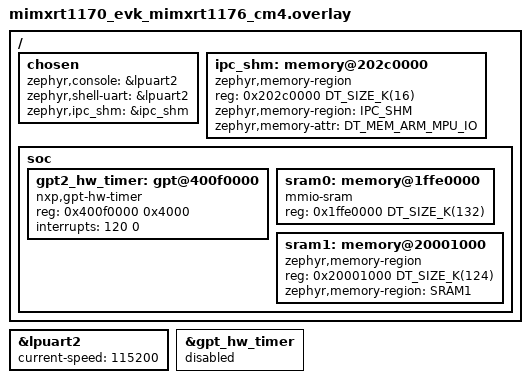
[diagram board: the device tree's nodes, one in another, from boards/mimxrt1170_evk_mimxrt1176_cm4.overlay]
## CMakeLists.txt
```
#
# Copyright 2026 NXP
#
# SPDX-License-Identifier: Apache-2.0
#

cmake_minimum_required(VERSION 3.20.0)
find_package(Zephyr REQUIRED HINTS $ENV{ZEPHYR_BASE})
find_program(ERPCGEN erpcgen REQUIRED)

project(remote)

set(ERPC_DIR ${CMAKE_CURRENT_LIST_DIR}/src/erpc)
add_custom_command(
    OUTPUT
        ${ERPC_DIR}/c_mp_zvid_transform_server.cpp
        ${ERPC_DIR}/mp_zvid_transform_server.cpp
        ${ERPC_DIR}/mp_zvid_transform_interface.cpp
    COMMAND
        ${ERPCGEN} -v -g c -o ${ERPC_DIR} ${ERPC_DIR}/mp_zvid_transform_server.erpc
    COMMAND
        ${CMAKE_COMMAND} -E rm -f ${ERPC_DIR}/*client.cpp ${ERPC_DIR}/*client.h ${ERPC_DIR}/*client.hpp
    DEPENDS
        ${ERPC_DIR}/mp_zvid_transform_server.erpc
)

target_sources(app PRIVATE
    src/main.c
    src/jpeg.c
    ${ERPC_DIR}/erpc_error_handler.c
    ${ERPC_DIR}/c_mp_zvid_transform_server.cpp
    ${ERPC_DIR}/mp_zvid_transform_server.cpp
    ${ERPC_DIR}/mp_zvid_transform_interface.cpp
)

# TODO: eRPC and rpmsg-lite should fix this dependency inversion by using Kconfig instead of
# including application-specific erpc_config.h and rpmsg_config.h back to the libraries
zephyr_include_directories(${CMAKE_CURRENT_SOURCE_DIR}/src/erpc)
zephyr_include_directories(${CMAKE_CURRENT_SOURCE_DIR}/src/erpc/rpmsg_lite)
```

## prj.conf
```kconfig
CONFIG_MAIN_STACK_SIZE=6000
CONFIG_HEAP_MEM_POOL_SIZE=8192

# RPC Configs

# C++ Language Support
CONFIG_CPP=y
CONFIG_NEWLIB_LIBC=y
CONFIG_GLIBCXX_LIBCPP=y

# eRPC
CONFIG_ERPC=y
CONFIG_ERPC_TRANSPORT_RPMSG_LITE=y

# RPMSG Lite
CONFIG_IPM=y
CONFIG_EVENTS=y
CONFIG_PRINTK=y
CONFIG_RPMSGLITE=y
CONFIG_RPMSGLITE_QUEUE=y
CONFIG_RPMSGLITE_NS=y
CONFIG_TIMESLICE_SIZE=1
```

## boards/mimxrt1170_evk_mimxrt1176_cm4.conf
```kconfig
# Multi-core support
CONFIG_BUILD_OUTPUT_INFO_HEADER=y
CONFIG_BUILD_OUTPUT_HEX=y
CONFIG_SECOND_CORE_MCUX=y
```

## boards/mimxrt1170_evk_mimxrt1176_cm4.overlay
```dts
/*
 * Copyright 2026 NXP
 *
 * SPDX-License-Identifier: Apache-2.0
 */

#include <zephyr/dt-bindings/memory-attr/memory-attr-arm.h>

/ {
	chosen {
		zephyr,console = &lpuart2;
		zephyr,shell-uart = &lpuart2;
		zephyr,ipc_shm = &ipc_shm;
	};

	/* OpenAMP fails with full 512K OCRAM2 memory region as shared memory */
	ipc_shm: memory@202c0000{
		compatible = "zephyr,memory-region", "mmio-sram";
		reg = <0x202c0000 DT_SIZE_K(16)>;
		zephyr,memory-region="IPC_SHM";
		zephyr,memory-attr = <DT_MEM_ARM_MPU_IO>;
	};

	soc {
		/delete-node/ gpt@400f0000;

		/* Replace GPT2 with another GPT kernel timer */
		gpt2_hw_timer: gpt@400f0000 {
			compatible = "nxp,gpt-hw-timer";
			reg = <0x400f0000 0x4000>;
			interrupts = <120 0>;
			status = "okay";
		};

		/* Expand M4 ITCM RAM_L to 4K more than default */
		sram0: memory@1ffe0000 {
			compatible = "mmio-sram";
			reg = <0x1ffe0000 DT_SIZE_K(132)>;
		};

		/* Shrink M4 DTCM RAM_U to 4K less than default */
		/delete-node/ memory@20000000;
		sram1: memory@20001000 {
			compatible = "zephyr,memory-region", "mmio-sram";
			reg = <0x20001000 DT_SIZE_K(124)>;
			zephyr,memory-region = "SRAM1";
		};
	};
};

/* Enable secondary LPUART */
&lpuart2 {
	status = "okay";
	current-speed = <115200>;
};

/* Disable primary GPT timer */
&gpt_hw_timer {
	status = "disabled";
};
```

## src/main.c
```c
/*
 * Copyright 2026 NXP
 *
 * SPDX-License-Identifier: BSD-3-Clause
 */

#include <errno.h>
#include <stdint.h>

#include <zephyr/devicetree.h>

#include "JPEGDEC.h"

#include "erpc_server_setup.h"
#include "erpc/c_mp_zvid_transform_server.h"
#include "erpc/erpc_error_handler.h"
#include "erpc/mp_zvid_transform_common.h"

#include "rpmsg_lite.h"

/* TODO: rpmsg-lite should define the link ID in devicetree instead of in rpmsg_platform.h */
#define ERPC_TRANSPORT_RPMSG_LITE_LINK_ID (RL_PLATFORM_IMXRT1170_M7_M4_LINK_ID)

#define SHM_MEM_ADDR DT_REG_ADDR(DT_CHOSEN(zephyr_ipc_shm))
#define SHM_MEM_SIZE DT_REG_SIZE(DT_CHOSEN(zephyr_ipc_shm))

/* Video stuffs picked from Zephyr's video.h */
#define VIDEO_FOURCC(a, b, c, d)                                                                   \
	((uint32_t)(a) | ((uint32_t)(b) << 8) | ((uint32_t)(c) << 16) | ((uint32_t)(d) << 24))

#define VIDEO_PIX_FMT_JPEG   VIDEO_FOURCC('J', 'P', 'E', 'G')
#define VIDEO_PIX_FMT_RGB565 VIDEO_FOURCC('R', 'G', 'B', 'P')

enum video_buf_type {
	/** input buffer type */
	VIDEO_BUF_TYPE_INPUT = 1,
	/** output buffer type */
	VIDEO_BUF_TYPE_OUTPUT = 2,
};

/* End of copied video stuffs */

#define JPEGDEC_WIDTH_MIN  64U
#define JPEGDEC_WIDTH_MAX  8192U
#define JPEGDEC_WIDTH_STEP 16U

#define JPEGDEC_FORMAT_CAP(pixfmt)                                                                 \
	{                                                                                          \
		.pixelformat = pixfmt,                                                             \
		.width_min = JPEGDEC_WIDTH_MIN,                                                    \
		.width_max = JPEGDEC_WIDTH_MAX,                                                    \
		.width_step = JPEGDEC_WIDTH_STEP,                                                  \
		.height_min = JPEGDEC_WIDTH_MIN,                                                   \
		.height_max = JPEGDEC_WIDTH_MAX,                                                   \
		.height_step = JPEGDEC_WIDTH_STEP,                                                 \
	}

static const video_format_cap jpegdec_in_caps[] = {
	JPEGDEC_FORMAT_CAP(VIDEO_PIX_FMT_JPEG),
};

static const video_format_cap jpegdec_out_caps[] = {
	JPEGDEC_FORMAT_CAP(VIDEO_PIX_FMT_RGB565),
};

static video_format out_fmt;
static JPEGIMAGE jpg;

int32_t get_buf_caps_rpc(mp_pad_direction direction, uint8_t *min_buffers, uint16_t *buf_align)
{
	*min_buffers = 1;
	*buf_align = 0;

	return 0;
}

int32_t get_format_caps_rpc(mp_pad_direction direction, uint8_t ind, video_format_cap *vfc)
{
	if (vfc == NULL || (direction != MP_PAD_SINK && direction != MP_PAD_SRC)) {
		return -EINVAL;
	}

	const video_format_cap *jcaps =
		(direction == MP_PAD_SINK) ? jpegdec_in_caps : jpegdec_out_caps;
	uint8_t size = (direction == MP_PAD_SINK) ? ARRAY_SIZE(jpegdec_in_caps)
						  : ARRAY_SIZE(jpegdec_out_caps);

	if (ind >= size) {
		return -ERANGE;
	}

	*vfc = jcaps[ind];

	return 0;
}

int32_t set_format_rpc(video_format *fmt)
{
	if (fmt->type != VIDEO_BUF_TYPE_INPUT && fmt->type != VIDEO_BUF_TYPE_OUTPUT) {
		return -EINVAL;
	}

	const video_format_cap *vfc =
		(fmt->type == VIDEO_BUF_TYPE_INPUT) ? jpegdec_in_caps : jpegdec_out_caps;
	uint8_t sz = (fmt->type == VIDEO_BUF_TYPE_INPUT) ? ARRAY_SIZE(jpegdec_in_caps)
							 : ARRAY_SIZE(jpegdec_out_caps);
	uint8_t i;

	for (i = 0; i < sz; i++) {
		if (fmt->pixelformat == vfc[i].pixelformat && fmt->width > vfc[i].width_min &&
		    fmt->width < vfc[i].width_max && fmt->height > vfc[i].height_min &&
		    fmt->height < vfc[i].height_max) {
			break;
		}
	}

	if (i == sz) {
		return -ENOTSUP;
	}

	/* TODO: Generalize to BPP and size config */
	if (fmt->type == VIDEO_BUF_TYPE_INPUT) {
		fmt->pitch = 0;
		fmt->size = 1314;
	} else {
		fmt->pitch = fmt->width * 2;
		fmt->size = fmt->pitch * fmt->height;
		out_fmt = *fmt;
	}

	return 0;
}

int transform_cap_rpc(mp_pad_direction direction, uint16_t ind, const video_format_cap *vfc,
		      video_format_cap *other_vfc)
{
	*other_vfc = *vfc;

	/* TODO: in range for output formats like PxP */
	if (direction == MP_PAD_SRC && vfc->pixelformat == VIDEO_PIX_FMT_JPEG &&
	    ind < ARRAY_SIZE(jpegdec_out_caps)) {
		other_vfc->pixelformat = jpegdec_out_caps[ind].pixelformat;
	} else if (direction == MP_PAD_SINK && vfc->pixelformat == VIDEO_PIX_FMT_RGB565 &&
		   ind < ARRAY_SIZE(jpegdec_in_caps)) {
		other_vfc->pixelformat = jpegdec_in_caps[ind].pixelformat;
	} else {
		return -EINVAL;
	}

	return 0;
}

bool chainfn_rpc(uint32_t in_buf, uint32_t in_sz, uint32_t out_buf, uint32_t *out_sz)
{
	if (JPEG_openRAM(&jpg, (uint8_t *)in_buf, in_sz, NULL) == 0) {
		printk("\r\nJPEG open failed\n");
		return false;
	}

	JPEG_setFramebuffer(&jpg, (void *)out_buf);

	/* TODO: Support more formats */
	switch (out_fmt.pixelformat) {
	case VIDEO_PIX_FMT_RGB565:
		JPEG_setPixelType(&jpg, RGB565_LITTLE_ENDIAN);
		break;
	default:
		return false;
	}

	if (JPEG_decode(&jpg, 0, 0, 0) == 0) {
		printk("\r\nJPEG decode failed\n");
		return false;
	}

	*out_sz = JPEG_getWidth(&jpg) * JPEG_getHeight(&jpg) * JPEG_getBpp(&jpg) / 8;

	return true;
}

static void SignalReady(void)
{
}

int main(void)
{
	printk("\r\nRemote started\n");
	/* TODO: 101U, 100U */
	erpc_transport_t transport = erpc_transport_rpmsg_lite_rtos_remote_init(
		101U, 100U, (void *)SHM_MEM_ADDR, ERPC_TRANSPORT_RPMSG_LITE_LINK_ID, SignalReady,
		NULL);
	erpc_mbf_t message_buffer_factory = erpc_mbf_rpmsg_init(transport);
	erpc_server_t server = erpc_server_init(transport, message_buffer_factory);
	erpc_service_t service = create_MPService_service();

	erpc_add_service_to_server(server, service);

	for (;;) {
		/* process message */
		erpc_status_t status = erpc_server_poll(server);

		/* handle error status */
		if (status != (erpc_status_t)kErpcStatus_Success) {
			/* print error description */
			erpc_error_handler(status, 0);

			/* removing the service from the server */
			erpc_remove_service_from_server(server, service);
			destroy_MPService_service(service); //

			/* stop erpc server */
			erpc_server_stop(server);

			/* print error description */
			erpc_server_deinit(server);

			/* exit program loop */
			break;
		}
	}
}
```
